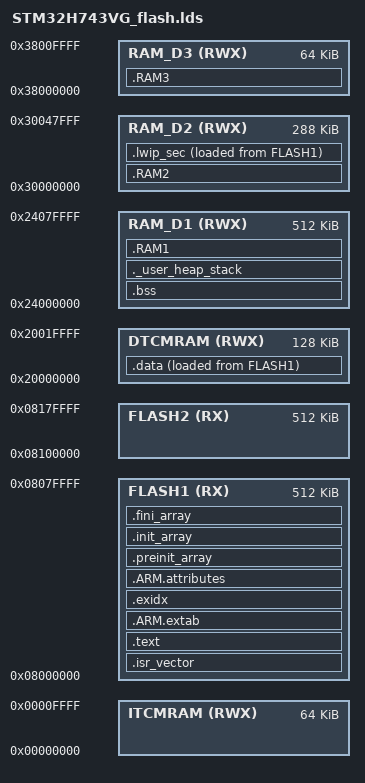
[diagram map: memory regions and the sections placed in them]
/* Generated by LinkerScriptGenerator [http://visualgdb.com/tools/LinkerScriptGenerator]
 * Target: STM32H743VG
 * The file is provided under the BSD license.
 */

ENTRY(Reset_Handler)

MEMORY
{
	DTCMRAM (RWX) : ORIGIN = 0x20000000, LENGTH = 128K
	RAM_D1 (RWX)  : ORIGIN = 0x24000000, LENGTH = 512K
	RAM_D2 (RWX)  : ORIGIN = 0x30000000, LENGTH = 288K
	RAM_D3 (RWX)  : ORIGIN = 0x38000000, LENGTH = 64K
	ITCMRAM (RWX) : ORIGIN = 0x00000000, LENGTH = 64K
	FLASH1 (RX)   : ORIGIN = 0x08000000, LENGTH = 512K
	FLASH2 (RX)   : ORIGIN = 0x08100000, LENGTH = 512K
}

_estack = 0x20020000;
_Min_Heap_Size = 0x4000;    
_Min_Stack_Size = 0x4000; 

SECTIONS
{
	.isr_vector :
	{
		. = ALIGN(4);
		KEEP(*(.isr_vector))
		. = ALIGN(4);
	} > FLASH1

	.text :
	{
		. = ALIGN(4);
		_stext = .;

		*(.text)
		*(.text*)
		*(.rodata)
		*(.rodata*)
		*(.glue_7)
		*(.glue_7t)
		KEEP(*(.init))
		KEEP(*(.fini))
		. = ALIGN(4);
		_etext = .;

	} > FLASH1

	.ARM.extab :
	{
		. = ALIGN(4);
		*(.ARM.extab)
		*(.gnu.linkonce.armextab.*)
		. = ALIGN(4);
	} > FLASH1

	.exidx :
	{
		. = ALIGN(4);
		PROVIDE(__exidx_start = .);
		*(.ARM.exidx*)
		. = ALIGN(4);
		PROVIDE(__exidx_end = .);
	} > FLASH1

	.ARM.attributes :
	{
		*(.ARM.attributes)
	} > FLASH1

	.preinit_array :
	{
		PROVIDE(__preinit_array_start = .);
		KEEP(*(.preinit_array*))
		PROVIDE(__preinit_array_end = .);
	} > FLASH1

	.init_array :
	{
		PROVIDE(__init_array_start = .);
		KEEP(*(SORT(.init_array.*)))
		KEEP(*(.init_array*))
		PROVIDE(__init_array_end = .);
	} > FLASH1

	.fini_array :
	{
		PROVIDE(__fini_array_start = .);
		KEEP(*(.fini_array*))
		KEEP(*(SORT(.fini_array.*)))
		PROVIDE(__fini_array_end = .);
	} > FLASH1

	.data :
	{
		. = ALIGN(4);
		_sdata = .;

		PROVIDE(__data_start__ = _sdata);
		*(.data)
		*(.data*)
		. = ALIGN(4);
		_edata = .;

		PROVIDE(__data_end__ = _edata);
	} > DTCMRAM AT >FLASH1

	_sidata = LOADADDR(.data);

	.bss :
	{
		. = ALIGN(4);
		_sbss = .;

		PROVIDE(__bss_start__ = _sbss);
		*(.bss)
		*(.bss*)
		*(COMMON)
		. = ALIGN(4);
		_ebss = .;

		PROVIDE(__bss_end__ = _ebss);
	} > RAM_D1

	._user_heap_stack :
	{
		. = ALIGN(8);
		PROVIDE ( end = . );
		PROVIDE ( _end = . );
		. = . + _Min_Heap_Size;
		. = . + _Min_Stack_Size;
		. = ALIGN(8);
	} >RAM_D1

	.ARM.attributes 0 : { *(.ARM.attributes) }

    .RAM1(NOLOAD) : 
	{
		. = ALIGN(4);
		*(.RAM1*)
	} > RAM_D1

    .RAM2(NOLOAD) : 
	{
		. = ALIGN(4);
		*(.RAM2*)
	} > RAM_D2

    .RAM3(NOLOAD) : 
	{
		. = ALIGN(4);
		*(.RAM3*)
	} > RAM_D3

  .lwip_sec (NOLOAD) : {
    . = ABSOLUTE(0x30040000);
    *(.RxDecripSection) 

    . = ABSOLUTE(0x30040060);
    *(.TxDecripSection)

    . = ABSOLUTE(0x30040200);
    *(.RxArraySection) 
  } >RAM_D2 AT> FLASH1

}

